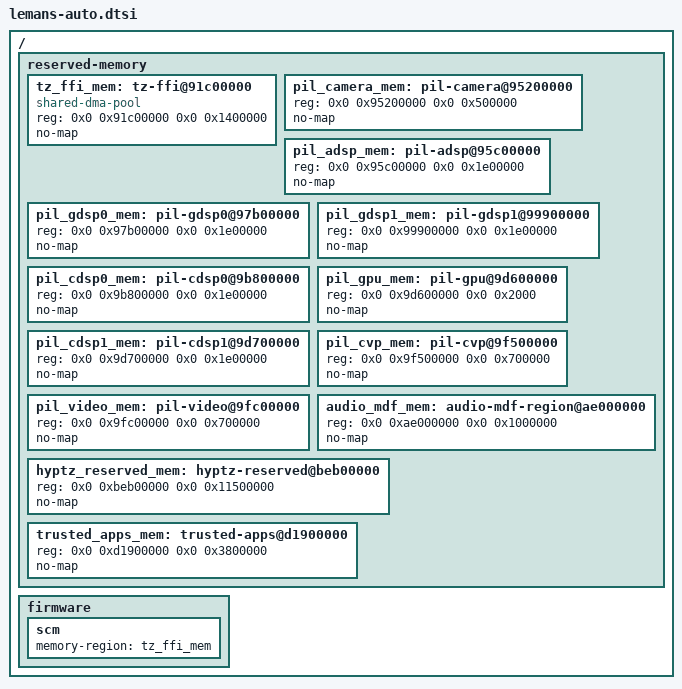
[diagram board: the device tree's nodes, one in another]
// SPDX-License-Identifier: BSD-3-Clause
/*
 * Copyright (c) 2023, Linaro Limited
 */

/dts-v1/;

#include "lemans.dtsi"

/delete-node/ &pil_camera_mem;
/delete-node/ &pil_adsp_mem;
/delete-node/ &q6_adsp_dtb_mem;
/delete-node/ &q6_gdsp0_dtb_mem;
/delete-node/ &pil_gdsp0_mem;
/delete-node/ &pil_gdsp1_mem;
/delete-node/ &q6_gdsp1_dtb_mem;
/delete-node/ &q6_cdsp0_dtb_mem;
/delete-node/ &pil_cdsp0_mem;
/delete-node/ &pil_gpu_mem;
/delete-node/ &pil_cdsp1_mem;
/delete-node/ &q6_cdsp1_dtb_mem;
/delete-node/ &pil_cvp_mem;
/delete-node/ &pil_video_mem;
/delete-node/ &gunyah_md_mem;

/ {
	reserved-memory {
		#address-cells = <2>;
		#size-cells = <2>;
		ranges;

		tz_ffi_mem: tz-ffi@91c00000 {
			compatible = "shared-dma-pool";
			reg = <0x0 0x91c00000 0x0 0x1400000>;
			no-map;
		};

		pil_camera_mem: pil-camera@95200000 {
			reg = <0x0 0x95200000 0x0 0x500000>;
			no-map;
		};

		pil_adsp_mem: pil-adsp@95c00000 {
			reg = <0x0 0x95c00000 0x0 0x1e00000>;
			no-map;
		};

		pil_gdsp0_mem: pil-gdsp0@97b00000 {
			reg = <0x0 0x97b00000 0x0 0x1e00000>;
			no-map;
		};

		pil_gdsp1_mem: pil-gdsp1@99900000 {
			reg = <0x0 0x99900000 0x0 0x1e00000>;
			no-map;
		};

		pil_cdsp0_mem: pil-cdsp0@9b800000 {
			reg = <0x0 0x9b800000 0x0 0x1e00000>;
			no-map;
		};

		pil_gpu_mem: pil-gpu@9d600000 {
			reg = <0x0 0x9d600000 0x0 0x2000>;
			no-map;
		};

		pil_cdsp1_mem: pil-cdsp1@9d700000 {
			reg = <0x0 0x9d700000 0x0 0x1e00000>;
			no-map;
		};

		pil_cvp_mem: pil-cvp@9f500000 {
			reg = <0x0 0x9f500000 0x0 0x700000>;
			no-map;
		};

		pil_video_mem: pil-video@9fc00000 {
			reg = <0x0 0x9fc00000 0x0 0x700000>;
			no-map;
		};

		audio_mdf_mem: audio-mdf-region@ae000000 {
			reg = <0x0 0xae000000 0x0 0x1000000>;
			no-map;
		};

		hyptz_reserved_mem: hyptz-reserved@beb00000 {
			reg = <0x0 0xbeb00000 0x0 0x11500000>;
			no-map;
		};

		trusted_apps_mem: trusted-apps@d1900000 {
			reg = <0x0 0xd1900000 0x0 0x3800000>;
			no-map;
		};
	};

	firmware {
		scm {
			memory-region = <&tz_ffi_mem>;
		};
	};
};
